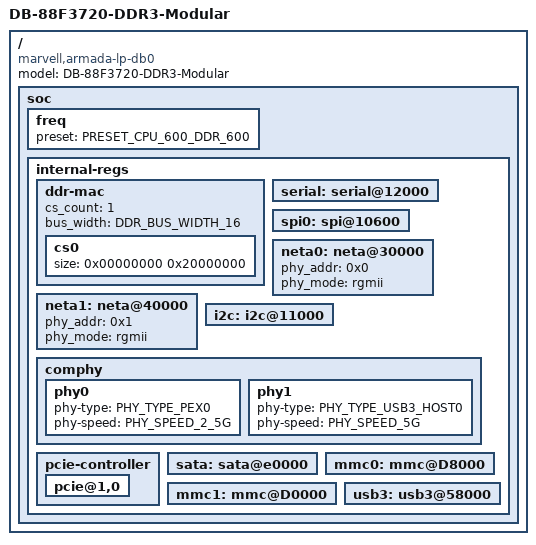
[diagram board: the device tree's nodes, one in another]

/dts-v1/;
#include <dt-bindings/ddr/ddr_data.h>
#include "armada-lp.dtsi"

/* detail board setup:
 * Pcie Jumper slot	:	DB-88F3720-PCIe-mPCIe-Jumper
 * SGMII module slot	:	DB-88F3720-SerDes-Jumper
 * RGMII module slot	:	DB-88F3720-PHY module
 * eMMC slot		:	DB-88F3720-eMMC_NAND module
 * SDIO slot		:	DB-88F3720-SDcard module
 *
 * PHY0 (USB3/SGMII1)	:	USB3
 * PHY1 (PCIe/SGMII0)	:	PCIe (WiFi via mini_PCIe module)
 * PHY2 (SATA)		:	SATA
 * RGMII-0		:	Ethernet via PHY (1 Lane)
 * RGMII-1		:	Ethernet via PHY (1 Lane)
 * USB2 Port 0		:	USB2 as part USB3
 * USB2 Port 1		:	USB2 Host
 * eMMC*		:	eMMC NAND
 * SDIO*		:	SD card
 * BOOT device*		:	SPI Flash
*/

/ {
	model = "DB-88F3720-DDR3-Modular";
	compatible = "marvell,armada-lp-db0", "marvell,armada-lp";

	soc {
		freq {
			preset = <PRESET_CPU_600_DDR_600>;
		};

		internal-regs {
			ddr-mac {
				cs_count = <1>;
				bus_width = <DDR_BUS_WIDTH_16>;
				cs0 {
					size = <0x00000000 0x20000000>;
				};
			};
			serial: serial@12000 {
				status = "okay";
			};
			spi0: spi@10600 {
				status = "okay";
			};
			neta0: neta@30000 {
				status = "okay";
				phy_addr = <0x0>;
				phy_mode = "rgmii";
			};
			neta1: neta@40000 {
				status = "okay";
				phy_addr = <0x1>;
				phy_mode = "rgmii";
			};
			i2c: i2c@11000 {
				status = "okay";
			};
			comphy {
				phy0 {
					phy-type = <PHY_TYPE_PEX0>;
					phy-speed = <PHY_SPEED_2_5G>;
				};
				phy1 {
					phy-type = <PHY_TYPE_USB3_HOST0>;
					phy-speed = <PHY_SPEED_5G>;
				};
			};
			pcie-controller {
				pcie@1,0 {
					status = "okay";
				};
			};
			sata: sata@e0000 {
				status = "okay";
			};
			mmc0: mmc@D8000 {
				status = "okay";
			};
			mmc1: mmc@D0000 {
				status = "okay";
			};
			usb3: usb3@58000 {
				status = "okay";
			};
		};
	};
};
